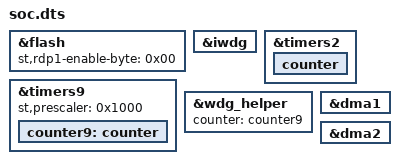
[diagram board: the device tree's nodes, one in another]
/* Copyright 2022 The ChromiumOS Authors.
 * Use of this source code is governed by a BSD-style license that can be
 * found in the LICENSE file.
 */

#include <cros/st/stm32f4.dtsi>

&flash {
	st,rdp1-enable-byte = <0x00>;
};

&iwdg {
        status = "okay";
};

&timers2 {
        status = "okay";
        counter {
                status = "okay";
        };
};

&timers9 {
	/*
	 * The counter has 16 bits. TIMPRE bit in RCC_DCKCFGR is 0 by default.
	 * On Dragonclaw board APB2 prescaler is set to 2. In this case APB2
	 * clock is 48Mhz, but TIM9 input clock is doubled, because TIMPRE=0
	 * and APB2 prescaler > 1. Effectively TIM9 is clocked with 96Mhz clock.
	 * Setting prescaler to 4096 will give about 2.8s maximum timeout.
	 */
	st,prescaler = <0x1000>;
        status = "okay";
        counter9: counter {
                status = "okay";
        };
};

&wdg_helper {
	counter = <&counter9>;
	status = "okay";
};

&dma1 {
        status = "okay";
};

&dma2 {
        status = "okay";
};
